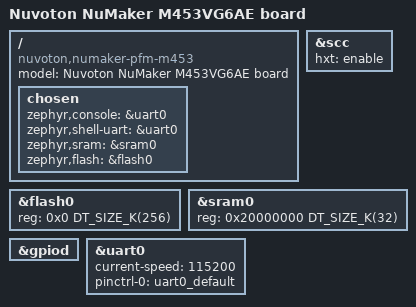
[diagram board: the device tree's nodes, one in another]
/*
 * Copyright (c) 2024 Nuvoton Technology Corporation.
 *
 * SPDX-License-Identifier: Apache-2.0
 */

/dts-v1/;
#include <nuvoton/m45x.dtsi>
#include "numaker_pfm_m453-pinctrl.dtsi"

/ {
	model = "Nuvoton NuMaker M453VG6AE board";
	compatible = "nuvoton,numaker-pfm-m453", "nuvoton,m453";

	chosen {
		zephyr,console = &uart0;
		zephyr,shell-uart = &uart0;
		zephyr,sram = &sram0;
		zephyr,flash = &flash0;
	};
};

&scc {
	hxt = "enable";
};

&flash0 {
	reg = <0x0 DT_SIZE_K(256)>;
};

&sram0 {
	reg = <0x20000000 DT_SIZE_K(32)>;
};

&gpiod {
	status = "okay";
};

&uart0 {
	current-speed = <115200>;
	status = "okay";
	pinctrl-0 = <&uart0_default>;
	pinctrl-names = "default";
};
